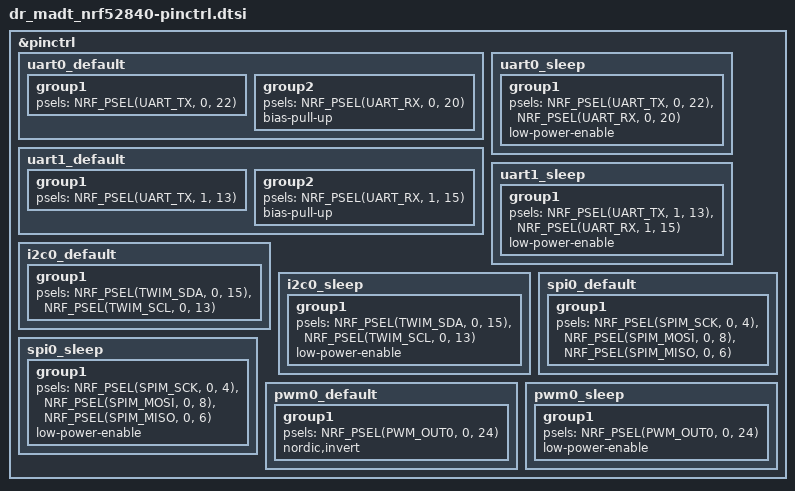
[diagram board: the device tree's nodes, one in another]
/*
 * Copyright (c) 2022 Caspar Friedrich <c.s.w.friedrich@gmail.com>
 *
 * SPDX-License-Identifier: Apache-2.0
 */

&pinctrl {
	uart0_default: uart0_default {
		group1 {
			psels = <NRF_PSEL(UART_TX, 0, 22)>;
		};
		group2 {
			psels = <NRF_PSEL(UART_RX, 0, 20)>;
			bias-pull-up;
		};
	};

	uart0_sleep: uart0_sleep {
		group1 {
			psels = <NRF_PSEL(UART_TX, 0, 22)>,
				<NRF_PSEL(UART_RX, 0, 20)>;
			low-power-enable;
		};
	};

	uart1_default: uart1_default {
		group1 {
			psels = <NRF_PSEL(UART_TX, 1, 13)>;
		};
		group2 {
			psels = <NRF_PSEL(UART_RX, 1, 15)>;
			bias-pull-up;
		};
	};

	uart1_sleep: uart1_sleep {
		group1 {
			psels = <NRF_PSEL(UART_TX, 1, 13)>,
				<NRF_PSEL(UART_RX, 1, 15)>;
			low-power-enable;
		};
	};

	i2c0_default: i2c0_default {
		group1 {
			psels = <NRF_PSEL(TWIM_SDA, 0, 15)>,
				<NRF_PSEL(TWIM_SCL, 0, 13)>;
			// nordic,drive-mode = <NRF_DRIVE_S0D1>;
		};
	};

	i2c0_sleep: i2c0_sleep {
		group1 {
			psels = <NRF_PSEL(TWIM_SDA, 0, 15)>,
				<NRF_PSEL(TWIM_SCL, 0, 13)>;
			low-power-enable;
		};
	};

	spi0_default: spi0_default {
		group1 {
			psels = <NRF_PSEL(SPIM_SCK, 0, 4)>,
				<NRF_PSEL(SPIM_MOSI, 0, 8)>,
				<NRF_PSEL(SPIM_MISO, 0, 6)>;
		};
	};

	spi0_sleep: spi0_sleep {
		group1 {
			psels = <NRF_PSEL(SPIM_SCK, 0, 4)>,
				<NRF_PSEL(SPIM_MOSI, 0, 8)>,
				<NRF_PSEL(SPIM_MISO, 0, 6)>;
			low-power-enable;
		};
	};

	pwm0_default: pwm0_default {
		group1 {
			psels = <NRF_PSEL(PWM_OUT0, 0, 24)>;
			nordic,invert;
		};
	};

	pwm0_sleep: pwm0_sleep {
		group1 {
			psels = <NRF_PSEL(PWM_OUT0, 0, 24)>;
			low-power-enable;
		};
	};
};
